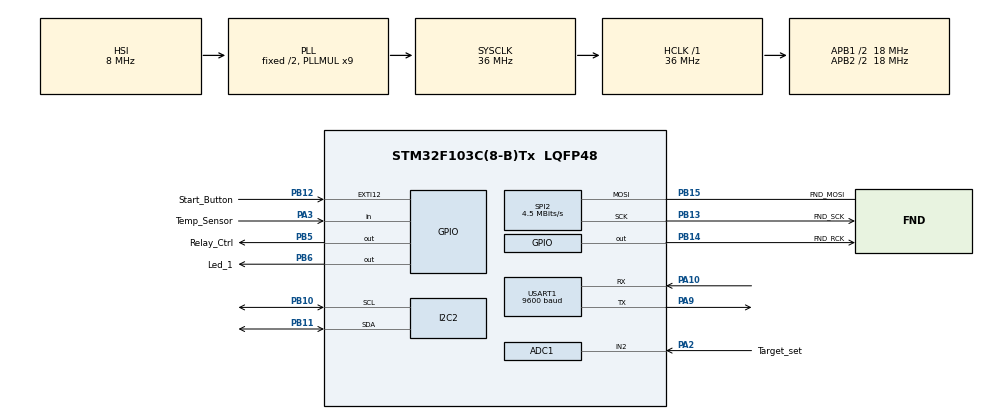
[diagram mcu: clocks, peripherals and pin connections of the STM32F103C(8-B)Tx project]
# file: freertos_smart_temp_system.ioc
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ADC1.Channel-0\#ChannelRegularConversion=ADC_CHANNEL_2
ADC1.NbrOfConversionFlag=1
ADC1.Rank-0\#ChannelRegularConversion=1
ADC1.SamplingTime-0\#ChannelRegularConversion=ADC_SAMPLETIME_1CYCLE_5
ADC1.master=1
FREERTOS.Tasks01=defaultTask,24,128,StartDefaultTask,Default,NULL,Dynamic,NULL,NULL
FREERTOS.configTOTAL_HEAP_SIZE=8 * 1024
Mcu.Family=STM32F1
Mcu.Name=STM32F103C(8-B)Tx
Mcu.Package=LQFP48
NVIC.EXTI15_10_IRQn=true\:5\:0\:false\:false\:true\:false\:true\:true\:true
NVIC.PriorityGroup=NVIC_PRIORITYGROUP_4
NVIC.USART1_IRQn=true\:5\:0\:false\:false\:true\:true\:true\:true\:true
PA10.Mode=Asynchronous
PA10.Signal=USART1_RX
PA13.Mode=Serial_Wire
PA13.Signal=SYS_JTMS-SWDIO
PA14.Mode=Serial_Wire
PA14.Signal=SYS_JTCK-SWCLK
PA2.GPIO_Label=Target_set
PA2.GPIO_Mode=GPIO_MODE_ANALOG
PA2.Signal=SharedAnalog_PA2
PA3.GPIO_Label=Temp_Sensor
PA3.GPIO_PuPd=GPIO_PULLUP
PA3.Signal=GPIO_Input
PA9.Mode=Asynchronous
PA9.Signal=USART1_TX
PB10.Mode=I2C
PB10.Signal=I2C2_SCL
PB11.Mode=I2C
PB11.Signal=I2C2_SDA
PB12.GPIO_Label=Start_Button
PB12.GPIO_PuPd=GPIO_PULLUP
PB12.Signal=GPXTI12
PB13.GPIO_Label=FND_SCK
PB13.Mode=Simplex_Bidirectional_Master
PB13.Signal=SPI2_SCK
PB14.GPIO_Label=FND_RCK
PB14.GPIO_PuPd=GPIO_PULLUP
PB14.GPIO_Speed=GPIO_SPEED_FREQ_HIGH
PB14.Signal=GPIO_Output
PB15.GPIO_Label=FND_MOSI
PB15.Mode=Simplex_Bidirectional_Master
PB15.Signal=SPI2_MOSI
PB5.GPIO_Label=Relay_Ctrl
PB5.GPIO_PuPd=GPIO_PULLUP
PB5.Signal=GPIO_Output
PB6.GPIO_Label=Led_1
PB6.GPIO_PuPd=GPIO_PULLUP
PB6.Signal=GPIO_Output
ProjectManager.HeapSize=0x200
ProjectManager.StackSize=0x400
ProjectManager.TargetToolchain=STM32CubeIDE
RCC.AHBFreq_Value=36000000
RCC.APB1CLKDivider=RCC_HCLK_DIV2
RCC.APB1Freq_Value=18000000
RCC.APB1TimFreq_Value=36000000
RCC.APB2CLKDivider=RCC_HCLK_DIV2
RCC.APB2Freq_Value=18000000
RCC.APB2TimFreq_Value=36000000
RCC.HCLKFreq_Value=36000000
RCC.PLLMUL=RCC_PLL_MUL9
RCC.SYSCLKFreq_VALUE=36000000
RCC.SYSCLKSource=RCC_SYSCLKSOURCE_PLLCLK
RCC.USBFreq_Value=36000000
SH.SharedAnalog_PA2.0=GPIO_Analog
SH.SharedAnalog_PA2.1=ADC1_IN2,IN2
SPI2.BaudRatePrescaler=SPI_BAUDRATEPRESCALER_4
SPI2.CalculateBaudRate=4.5 MBits/s
SPI2.Direction=SPI_DIRECTION_1LINE
SPI2.Mode=SPI_MODE_MASTER
SPI2.VirtualType=VM_MASTER
TIM2.Prescaler=35
USART1.BaudRate=9600
USART1.VirtualMode=VM_ASYNC
VP_FREERTOS_VS_CMSIS_V2.Mode=CMSIS_V2
VP_TIM2_VS_ClockSourceINT.Mode=Internal
board=custom

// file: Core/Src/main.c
/* USER CODE BEGIN Header */
/**
  ******************************************************************************
  * @file           : main.c
  * @brief          : Main program body
  ******************************************************************************
  * @attention
  *
  * Copyright (c) 2026 STMicroelectronics.
  * All rights reserved.
  *
  * This software is licensed under terms that can be found in the LICENSE file
  * in the root directory of this software component.
  * If no LICENSE file comes with this software, it is provided AS-IS.
  *
  ******************************************************************************
  */
/* USER CODE END Header */
#include "main.h"
#include "cmsis_os.h"

/* USER CODE BEGIN Includes */
#include "Temp_FreeRtos.h"
/* USER CODE END Includes */

ADC_HandleTypeDef hadc1;

I2C_HandleTypeDef hi2c2;

SPI_HandleTypeDef hspi2;

TIM_HandleTypeDef htim2;

UART_HandleTypeDef huart1;

/* Definitions for defaultTask */
osThreadId_t defaultTaskHandle;
const osThreadAttr_t defaultTask_attributes = {
  .name = "defaultTask",
  .stack_size = 128 * 4,
  .priority = (osPriority_t) osPriorityNormal,
};

void SystemClock_Config(void);
static void MX_GPIO_Init(void);
static void MX_I2C2_Init(void);
static void MX_SPI2_Init(void);
static void MX_USART1_UART_Init(void);
static void MX_ADC1_Init(void);
static void MX_TIM2_Init(void);
void StartDefaultTask(void *argument);

int main(void)
{

  /* MCU Configuration--------------------------------------------------------*/

  /* Reset of all peripherals, Initializes the Flash interface and the Systick. */
  HAL_Init();

  /* Configure the system clock */
  SystemClock_Config();

  /* Initialize all configured peripherals */
  MX_GPIO_Init();
  MX_I2C2_Init();
  MX_SPI2_Init();
  MX_USART1_UART_Init();
  MX_ADC1_Init();
  MX_TIM2_Init();

  /* Init scheduler */
  osKernelInitialize();

  /* USER CODE BEGIN RTOS_MUTEX */
  /* add mutexes, ... */
  Mutex_Init();
  /* USER CODE END RTOS_MUTEX */

  /* USER CODE BEGIN RTOS_SEMAPHORES */
  /* add semaphores, ... */
  Semaphore_Init();
  /* USER CODE END RTOS_SEMAPHORES */

  /* USER CODE BEGIN RTOS_TIMERS */
  /* start timers, add new ones, ... */
  HAL_TIM_Base_Start(&htim2);

  /* USER CODE END RTOS_TIMERS */

  /* Create the thread(s) */
  /* creation of defaultTask */
  //defaultTaskHandle = osThreadNew(StartDefaultTask, NULL, &defaultTask_attributes);

  /* USER CODE BEGIN RTOS_THREADS */
  /* add threads, ... */
  FreeRtos_Init();
  /* USER CODE END RTOS_THREADS */

  /* USER CODE BEGIN RTOS_EVENTS */
  /* add events, ... */

  vTaskStartScheduler(); // start scheduler
  /* USER CODE END RTOS_EVENTS */

  /* Start scheduler */
  //osKernelStart();

  /* We should never get here as control is now taken by the scheduler */

  /* Infinite loop */
  while (1)
  {

  }
}

void SystemClock_Config(void)
{
  RCC_OscInitTypeDef RCC_OscInitStruct = {0};
  RCC_ClkInitTypeDef RCC_ClkInitStruct = {0};
  RCC_PeriphCLKInitTypeDef PeriphClkInit = {0};

  /** Initializes the RCC Oscillators according to the specified parameters
  * in the RCC_OscInitTypeDef structure.
  */
  RCC_OscInitStruct.OscillatorType = RCC_OSCILLATORTYPE_HSI;
  RCC_OscInitStruct.HSIState = RCC_HSI_ON;
  RCC_OscInitStruct.HSICalibrationValue = RCC_HSICALIBRATION_DEFAULT;
  RCC_OscInitStruct.PLL.PLLState = RCC_PLL_ON;
  RCC_OscInitStruct.PLL.PLLSource = RCC_PLLSOURCE_HSI_DIV2;
  RCC_OscInitStruct.PLL.PLLMUL = RCC_PLL_MUL9;
  if (HAL_RCC_OscConfig(&RCC_OscInitStruct) != HAL_OK)
  {
    Error_Handler();
  }

  /** Initializes the CPU, AHB and APB buses clocks
  */
  RCC_ClkInitStruct.ClockType = RCC_CLOCKTYPE_HCLK|RCC_CLOCKTYPE_SYSCLK
                              |RCC_CLOCKTYPE_PCLK1|RCC_CLOCKTYPE_PCLK2;
  RCC_ClkInitStruct.SYSCLKSource = RCC_SYSCLKSOURCE_PLLCLK;
  RCC_ClkInitStruct.AHBCLKDivider = RCC_SYSCLK_DIV1;
  RCC_ClkInitStruct.APB1CLKDivider = RCC_HCLK_DIV2;
  RCC_ClkInitStruct.APB2CLKDivider = RCC_HCLK_DIV2;

  if (HAL_RCC_ClockConfig(&RCC_ClkInitStruct, FLASH_LATENCY_1) != HAL_OK)
  {
    Error_Handler();
  }
  PeriphClkInit.PeriphClockSelection = RCC_PERIPHCLK_ADC;
  PeriphClkInit.AdcClockSelection = RCC_ADCPCLK2_DIV2;
  if (HAL_RCCEx_PeriphCLKConfig(&PeriphClkInit) != HAL_OK)
  {
    Error_Handler();
  }
}

static void MX_ADC1_Init(void)
{

  ADC_ChannelConfTypeDef sConfig = {0};

  /** Common config
  */
  hadc1.Instance = ADC1;
  hadc1.Init.ScanConvMode = ADC_SCAN_DISABLE;
  hadc1.Init.ContinuousConvMode = DISABLE;
  hadc1.Init.DiscontinuousConvMode = DISABLE;
  hadc1.Init.ExternalTrigConv = ADC_SOFTWARE_START;
  hadc1.Init.DataAlign = ADC_DATAALIGN_RIGHT;
  hadc1.Init.NbrOfConversion = 1;
  if (HAL_ADC_Init(&hadc1) != HAL_OK)
  {
    Error_Handler();
  }

  /** Configure Regular Channel
  */
  sConfig.Channel = ADC_CHANNEL_2;
  sConfig.Rank = ADC_REGULAR_RANK_1;
  sConfig.SamplingTime = ADC_SAMPLETIME_1CYCLE_5;
  if (HAL_ADC_ConfigChannel(&hadc1, &sConfig) != HAL_OK)
  {
    Error_Handler();
  }

}

static void MX_I2C2_Init(void)
{

  hi2c2.Instance = I2C2;
  hi2c2.Init.ClockSpeed = 100000;
  hi2c2.Init.DutyCycle = I2C_DUTYCYCLE_2;
  hi2c2.Init.OwnAddress1 = 0;
  hi2c2.Init.AddressingMode = I2C_ADDRESSINGMODE_7BIT;
  hi2c2.Init.DualAddressMode = I2C_DUALADDRESS_DISABLE;
  hi2c2.Init.OwnAddress2 = 0;
  hi2c2.Init.GeneralCallMode = I2C_GENERALCALL_DISABLE;
  hi2c2.Init.NoStretchMode = I2C_NOSTRETCH_DISABLE;
  if (HAL_I2C_Init(&hi2c2) != HAL_OK)
  {
    Error_Handler();
  }

}

static void MX_SPI2_Init(void)
{

  /* SPI2 parameter configuration*/
  hspi2.Instance = SPI2;
  hspi2.Init.Mode = SPI_MODE_MASTER;
  hspi2.Init.Direction = SPI_DIRECTION_1LINE;
  hspi2.Init.DataSize = SPI_DATASIZE_8BIT;
  hspi2.Init.CLKPolarity = SPI_POLARITY_LOW;
  hspi2.Init.CLKPhase = SPI_PHASE_1EDGE;
  hspi2.Init.NSS = SPI_NSS_SOFT;
  hspi2.Init.BaudRatePrescaler = SPI_BAUDRATEPRESCALER_4;
  hspi2.Init.FirstBit = SPI_FIRSTBIT_MSB;
  hspi2.Init.TIMode = SPI_TIMODE_DISABLE;
  hspi2.Init.CRCCalculation = SPI_CRCCALCULATION_DISABLE;
  hspi2.Init.CRCPolynomial = 10;
  if (HAL_SPI_Init(&hspi2) != HAL_OK)
  {
    Error_Handler();
  }

}

static void MX_TIM2_Init(void)
{

  TIM_ClockConfigTypeDef sClockSourceConfig = {0};
  TIM_MasterConfigTypeDef sMasterConfig = {0};

  htim2.Instance = TIM2;
  htim2.Init.Prescaler = 35;
  htim2.Init.CounterMode = TIM_COUNTERMODE_UP;
  htim2.Init.Period = 65535;
  htim2.Init.ClockDivision = TIM_CLOCKDIVISION_DIV1;
  htim2.Init.AutoReloadPreload = TIM_AUTORELOAD_PRELOAD_DISABLE;
  if (HAL_TIM_Base_Init(&htim2) != HAL_OK)
  {
    Error_Handler();
  }
  sClockSourceConfig.ClockSource = TIM_CLOCKSOURCE_INTERNAL;
  if (HAL_TIM_ConfigClockSource(&htim2, &sClockSourceConfig) != HAL_OK)
  {
    Error_Handler();
  }
  sMasterConfig.MasterOutputTrigger = TIM_TRGO_RESET;
  sMasterConfig.MasterSlaveMode = TIM_MASTERSLAVEMODE_DISABLE;
  if (HAL_TIMEx_MasterConfigSynchronization(&htim2, &sMasterConfig) != HAL_OK)
  {
    Error_Handler();
  }

}

static void MX_USART1_UART_Init(void)
{

  huart1.Instance = USART1;
  huart1.Init.BaudRate = 9600;
  huart1.Init.WordLength = UART_WORDLENGTH_8B;
  huart1.Init.StopBits = UART_STOPBITS_1;
  huart1.Init.Parity = UART_PARITY_NONE;
  huart1.Init.Mode = UART_MODE_TX_RX;
  huart1.Init.HwFlowCtl = UART_HWCONTROL_NONE;
  huart1.Init.OverSampling = UART_OVERSAMPLING_16;
  if (HAL_UART_Init(&huart1) != HAL_OK)
  {
    Error_Handler();
  }

}

static void MX_GPIO_Init(void)
{
  GPIO_InitTypeDef GPIO_InitStruct = {0};

  /* GPIO Ports Clock Enable */
  __HAL_RCC_GPIOA_CLK_ENABLE();
  __HAL_RCC_GPIOB_CLK_ENABLE();

  /*Configure GPIO pin Output Level */
  HAL_GPIO_WritePin(GPIOB, FND_RCK_Pin|Relay_Ctrl_Pin|Led_1_Pin, GPIO_PIN_RESET);

  /*Configure GPIO pin : Temp_Sensor_Pin */
  GPIO_InitStruct.Pin = Temp_Sensor_Pin;
  GPIO_InitStruct.Mode = GPIO_MODE_INPUT;
  GPIO_InitStruct.Pull = GPIO_PULLUP;
  HAL_GPIO_Init(Temp_Sensor_GPIO_Port, &GPIO_InitStruct);

  /*Configure GPIO pin : Start_Button_Pin */
  GPIO_InitStruct.Pin = Start_Button_Pin;
  GPIO_InitStruct.Mode = GPIO_MODE_IT_RISING;
  GPIO_InitStruct.Pull = GPIO_PULLUP;
  HAL_GPIO_Init(Start_Button_GPIO_Port, &GPIO_InitStruct);

  /*Configure GPIO pin : FND_RCK_Pin */
  GPIO_InitStruct.Pin = FND_RCK_Pin;
  GPIO_InitStruct.Mode = GPIO_MODE_OUTPUT_PP;
  GPIO_InitStruct.Pull = GPIO_PULLUP;
  GPIO_InitStruct.Speed = GPIO_SPEED_FREQ_HIGH;
  HAL_GPIO_Init(FND_RCK_GPIO_Port, &GPIO_InitStruct);

  /*Configure GPIO pins : Relay_Ctrl_Pin Led_1_Pin */
  GPIO_InitStruct.Pin = Relay_Ctrl_Pin|Led_1_Pin;
  GPIO_InitStruct.Mode = GPIO_MODE_OUTPUT_PP;
  GPIO_InitStruct.Pull = GPIO_PULLUP;
  GPIO_InitStruct.Speed = GPIO_SPEED_FREQ_LOW;
  HAL_GPIO_Init(GPIOB, &GPIO_InitStruct);

  /* EXTI interrupt init*/
  HAL_NVIC_SetPriority(EXTI15_10_IRQn, 5, 0);
  HAL_NVIC_EnableIRQ(EXTI15_10_IRQn);

}

void StartDefaultTask(void *argument)
{
  for(;;)
  {
    osDelay(1);
  }
}

void Error_Handler(void)
{
  __disable_irq();
  while (1)
  {
  }
}
